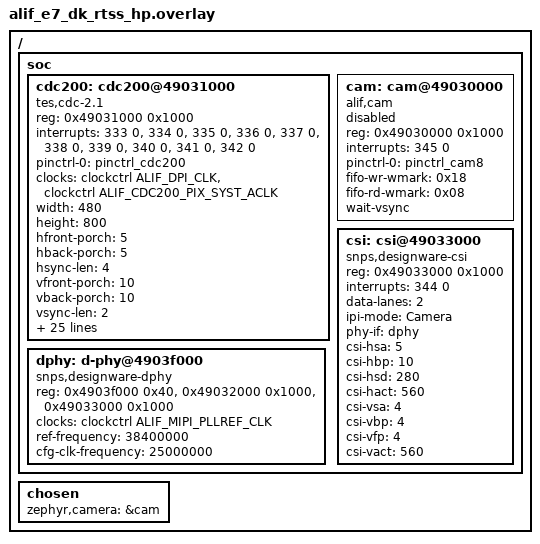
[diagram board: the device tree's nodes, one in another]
#include <zephyr/dt-bindings/mipi_dsi/mipi_dsi.h>

/ {
	soc {
		cdc200: cdc200@49031000 {
			compatible = "tes,cdc-2.1";
			reg = <0x49031000 0x1000>;
			status = "okay";
			interrupts =	<333 0>,
					<334 0>,
					<335 0>,
					<336 0>,
					<337 0>,
					<338 0>,
					<339 0>,
					<340 0>,
					<341 0>,
					<342 0>;
			interrupt-names = "scanline_0",
					"scanline_1",
					"fifo_warning_0",
					"fifo_warning_1",
					"fifo_underrun_0",
					"fifo_underrun_1",
					"bus_error_0",
					"bus_error_1",
					"reg_reload_0",
					"reg_reload_1";
			pinctrl-0 = < &pinctrl_cdc200 >;
			pinctrl-names = "default";

			clocks = <&clockctrl ALIF_DPI_CLK>, <&clockctrl ALIF_CDC200_PIX_SYST_ACLK>;
			clock-names = "dpi-clk-en", "pixel-clk";
			
			width = <480>;
			height = <800>;
			hfront-porch = <5>;
			hback-porch = <5>;
			hsync-len = <4>;
			vfront-porch = <10>;
			vback-porch = <10>;
			vsync-len = <2>;
			clock-frequency = <24364080>;
			hsync-active = <0>;
			vsync-active = <0>;
			de-active = <1>;
			pixelclk-active = <0>;
			bg-color = <0>;
			enable-l1 = <1>;
			pixel-fmt-l1 = "rgb-888";
			def-back-color-l1 = <0>;
			win-x0-l1 = <0>;
			win-y0-l1 = <0>;
			win-x1-l1 = <480>;
			win-y1-l1 = <800>;
			blend-factor1-l1 = <4>;
			blend-factor2-l1 = <5>;
			const-alpha-l1 = <0xff>;
			enable-l2 = <0>;
			pixel-fmt-l2 = "undefined";
			win-x0-l2 = <0>;
			win-y0-l2 = <0>;
			win-x1-l2 = <0>;
			win-y1-l2 = <0>;
			blend-factor1-l2 = <6>;
			blend-factor2-l2 = <7>;
			const-alpha-l2 = <0xff>;
		};

		dphy: d-phy@4903f000{
			compatible = "snps,designware-dphy";
			reg = <0x4903f000 0x40>,
				<0x49032000 0x1000>,
				<0x49033000 0x1000>;
			reg-names = "expmst_reg", "dsi_reg", "csi_reg";

			clocks = <&clockctrl ALIF_MIPI_PLLREF_CLK>;
			clock-names = "pllref-clk";

			ref-frequency = <38400000>;
			cfg-clk-frequency = <25000000>;
			status = "okay";
		};

		cam: cam@49030000 {
			compatible = "alif,cam";
			reg = <0x49030000 0x1000>;
			interrupts = <345 0>;
			pinctrl-0 = < &pinctrl_cam8 >;
			pinctrl-names = "default";

			fifo-wr-wmark = <0x18>;
			fifo-rd-wmark = <0x08>;
			wait-vsync;
			status = "disabled";
		};

		csi: csi@49033000 {
			compatible = "snps,designware-csi";
			reg = <0x49033000 0x1000>;
			interrupts = <344 0>;

			data-lanes = <2>;
			ipi-mode = "Camera";
			phy-if = <&dphy>;

			csi-hsa = <5>;
			csi-hbp = <10>;
			csi-hsd = <280>;
			csi-hact = <560>;
			csi-vsa = <4>;
			csi-vbp = <4>;
			csi-vfp = <4>;
			csi-vact = <560>;
		};
	};
};




/ {
	chosen {
		zephyr,camera = &cam;
	};
};
